# MM32SPINxxxx register map
Vendor: MindMotion Ltd.; Series: MM32SPIN; File version: 1.4
CPU: CM0 r0p0, little endian, no MPU, no FPU, 3 interrupt priority bits
Registers are 32-bit, read-write, reset 0x0 unless marked. A register's access mark holds for its fields unless they carry their own. Offsets are from the block's base; [hi:lo] are bit positions; {n}, {i} and the like mark numbered series.

## UART1 — Universal asynchronous receiver transmitter
Base 0x40013800
Same registers: UART2 0x40004400
0x00 TDR
  [7:0] TXREG — Transmit data register
0x04 RDR ro
  [7:0] RXREG — Receive data register
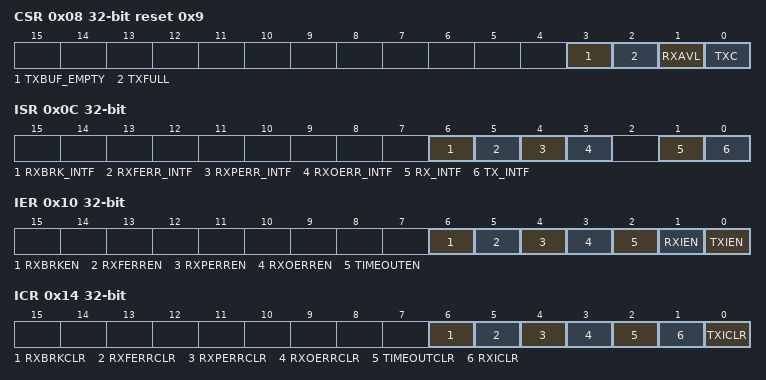
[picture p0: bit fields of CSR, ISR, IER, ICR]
0x08 CSR ro reset 0x9
  [3] TXBUF_EMPTY — Transmit buffer enpty flag bit
  [2] TXFULL — Transmit buffer full flag bit
  [1] RXAVL — Receive valid data flag bit
  [0] TXC — Transmit complete flag bit
0x0C ISR ro
  [6] RXBRK_INTF — Receive frame break interrupt flag bit
  [5] RXFERR_INTF — Frame error interrupt flag bit
  [4] RXPERR_INTF — Parity error interrupt flag bit
  [3] RXOERR_INTF — Receive overflow error interrupt flag bit
  [1] RX_INTF — Receive valid data interrupt flag bit
  [0] TX_INTF — Transmit buffer enpty interrupt flag bit
0x10 IER
  [6] RXBRKEN — Receive frame break interrupt enable bit
  [5] RXFERREN — Frame error interrupt enable bit
  [4] RXPERREN — Parity error interrupt enable bit
  [3] RXOERREN — Receive overflow error interrupt enable bit
  [2] TIMEOUTEN — Receive timeout interrupt enable bit
  [1] RXIEN — Receive buffer interrupt enable bit
  [0] TXIEN — Transmit buffer enpty interrupt enable bit
0x14 ICR wo
  [6] RXBRKCLR — Receive frame break interrupt clear bit
  [5] RXFERRCLR — Frame error interrupt clear bit
  [4] RXPERRCLR — Parity error interrupt clear bit
  [3] RXOERRCLR — Receive overflow error interrupt clear bit
  [2] TIMEOUTCLR — Receive timeout interrupt clear bit
  [1] RXICLR — Receive interrupt clear bit
  [0] TXICLR — Transmit buffer empty interrupt clear bit
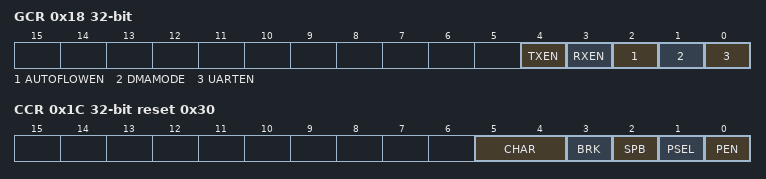
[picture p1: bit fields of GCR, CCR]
0x18 GCR
  [4] TXEN — Enable transmit
  [3] RXEN — Enable receive
  [2] AUTOFLOWEN — Automatic flow control enable bit
  [1] DMAMODE — DMA mode selection bit
  [0] UARTEN — UART mode selection bit
0x1C CCR reset 0x30
  [5:4] CHAR — UART width bit
  [3] BRK — UART transmit frame break
  [2] SPB — Stop bit selection
  [1] PSEL — Parity selection bit
  [0] PEN — Parity enable bit
0x20 BRR reset 0x1
  [15:0] DIV_Mantissa — UART baud rate control register
0x24 FRA
  [3:0] DIV_fraction — UART fractional-n control register

## ADC — Analog to digital converter
Base 0x40012400
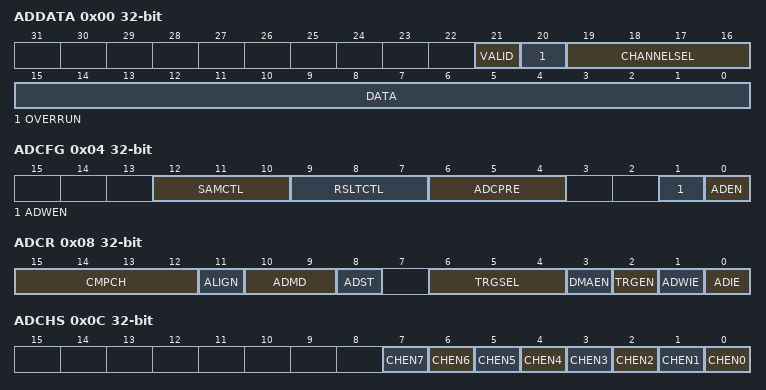
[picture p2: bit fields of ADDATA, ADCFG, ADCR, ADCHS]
0x00 ADDATA ro
  [21] VALID — Valid flag
  [20] OVERRUN — Overrun flag
  [19:16] CHANNELSEL — Channel selection
  [15:0] DATA — Transfer data
0x04 ADCFG
  [12:10] SAMCTL — Channel x Sample time selection
  [9:7] RSLTCTL — resolution
  [6:4] ADCPRE — ADC prescaler
  [1] ADWEN — ADC window comparison enable
  [0] ADEN — ADC enable
0x08 ADCR
  [15:12] CMPCH — Window comparison channel selection
  [11] ALIGN — Data alignment
  [10:9] ADMD — ADC mode
  [8] ADST — ADC start
  [6:4] TRGSEL — External trigger selection
  [3] DMAEN — Direct memory access enable
  [2] TRGEN — External trigger enable
  [1] ADWIE — ADC window comparator interrupt enable
  [0] ADIE — ADC interrupt enable
0x0C ADCHS
  [n] CHEN{n} (n=0..7) — Analog input channel {n} enable
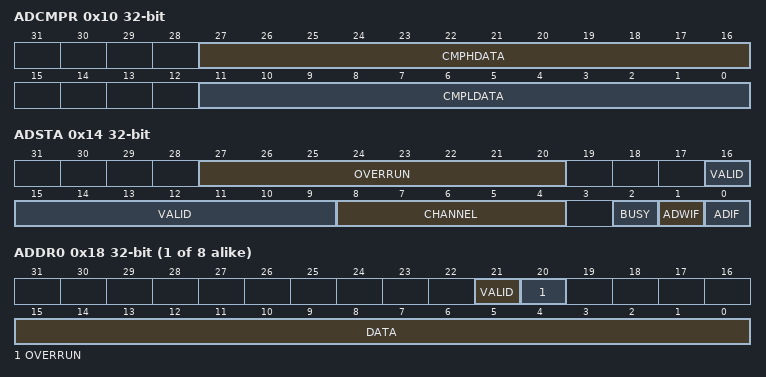
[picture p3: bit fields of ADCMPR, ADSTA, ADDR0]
0x10 ADCMPR
  [27:16] CMPHDATA — Compare data high limit
  [11:0] CMPLDATA — Compare data low limit
0x14 ADSTA ro
  [27:20] OVERRUN — Overrun flag
  [16:9] VALID — Valid flag
  [8:4] CHANNEL — Current conversion channel
  [2] BUSY
  [1] ADWIF — ADC window comparator interrupt flag
  [0] ADIF — ADC interrupt flag
{0x18+4i} ADDR{i} ro (i=0..7)
  [21] VALID — Valid flag
  [20] OVERRUN — Overrun flag
  [15:0] DATA — Transfer data

## USB — Universal serial bus full-speed device interface
Base 0x40005C00
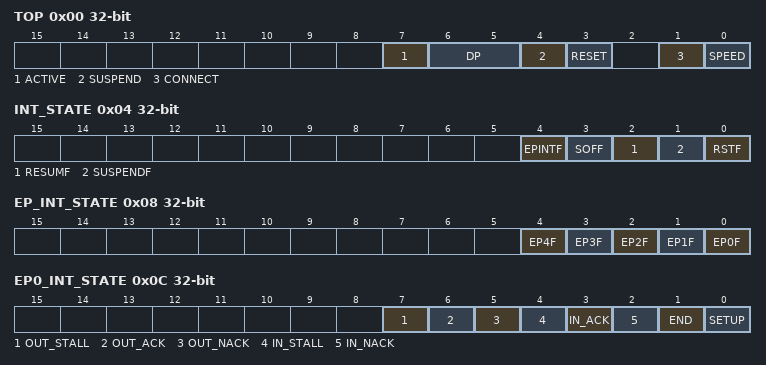
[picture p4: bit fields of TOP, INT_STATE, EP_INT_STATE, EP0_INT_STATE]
0x00 TOP
  [7] ACTIVE — USB bus is active
  [6:5] DP — Current USB DP/DM line state
  [4] SUSPEND — USB suspend state
  [3] RESET — Reset EP and FIFO in USB controller
  [1] CONNECT — USB connection
  [0] SPEED
0x04 INT_STATE ro
  [4] EPINTF — EP interrupt received
  [3] SOFF — BUS received
  [2] RESUMF — BUS resume received
  [1] SUSPENDF — BUS suspend received
  [0] RSTF — BUS reset received
0x08 EP_INT_STATE ro
  [n] EP{n}F (n=0..4) — EP{n} interrupt received
0x0C EP0_INT_STATE ro
  [7] OUT_STALL — OUT-STALL received
  [6] OUT_ACK — OUT-ACK received
  [5] OUT_NACK — OUT-NACK received
  [4] IN_STALL — IN-STALL received
  [3] IN_ACK — IN-ACK received
  [2] IN_NACK — IN-NACK received
  [1] END — Status stage finished
  [0] SETUP — SETUP packet received
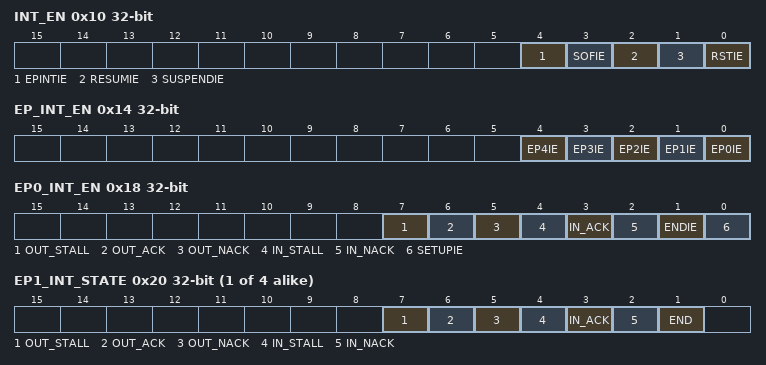
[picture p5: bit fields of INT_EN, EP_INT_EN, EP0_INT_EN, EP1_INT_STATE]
0x10 INT_EN
  [4] EPINTIE — EP interrupt enable
  [3] SOFIE — SOF interrupt enable
  [2] RESUMIE — BUS resume interrupt enable
  [1] SUSPENDIE — BUS suspend interrupt enable
  [0] RSTIE — BUS reset interrupt enable
0x14 EP_INT_EN
  [n] EP{n}IE (n=0..4) — EP{n} interrupt enable
0x18 EP0_INT_EN
  [7] OUT_STALL — OUT-STALL interrupt enable
  [6] OUT_ACK — OUT-ACK interrupt enable
  [5] OUT_NACK — OUT-NACK interrupt enable
  [4] IN_STALL — IN-STALL interrupt enable
  [3] IN_ACK — IN-ACK interrupt enable
  [2] IN_NACK — IN-NACK interrupt enable
  [1] ENDIE — Status stage finished interrupt enable
  [0] SETUPIE — SETUP packet interrupt enable
{0x1C+4i} EP{i}_INT_STATE (i=1..4)
  [7] OUT_STALL — OUT-STALL received
  [6] OUT_ACK — OUT-ACK received
  [5] OUT_NACK — OUT-NACK received
  [4] IN_STALL — IN-STALL received
  [3] IN_ACK — IN-ACK received
  [2] IN_NACK — IN-NACK received
  [1] END — Transfer finished
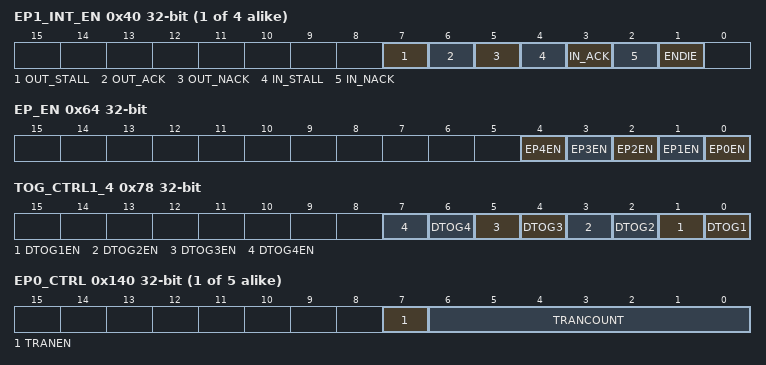
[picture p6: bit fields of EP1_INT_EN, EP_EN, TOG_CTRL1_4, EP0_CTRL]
{0x3C+4i} EP{i}_INT_EN (i=1..4)
  [7] OUT_STALL — OUT-STALL interrupt enable
  [6] OUT_ACK — OUT-ACK interrupt enable
  [5] OUT_NACK — OUT-NACK interrupt enable
  [4] IN_STALL — IN-STALL interrupt enable
  [3] IN_ACK — IN-ACK interrupt enable
  [2] IN_NACK — IN-NACK interrupt enable
  [1] ENDIE — Finished interrupt enable
0x60 ADDR
  [6:0] ADDR — USB address
0x64 EP_EN
  [n] EP{n}EN (n=0..4) — Enable End Point {n}
0x78 TOG_CTRL1_4
  [2n-1] DTOG{n}EN (n=1..4) — Set End Point {n} enable
  [2n-2] DTOG{n} (n=1..4) — Set End Point {n} Toggle
{0x80+4i} SETUP{i} ro (i=0..7)
  [7:0] SETUPD{i} — Setup Data {i}
0xA0 PACKET_SIZE reset 0x40
  [7:0] SIZE0 — USB DMA Max Packet Size
{0x100+4i} EP{i}_AVAIL ro (i=0..4)
  [7:0] EP{i}AVIL — EP{i} FIFO available data number
{0x140+4i} EP{i}_CTRL (i=0..4)
  [7] TRANEN — EP{i} transfer enable
  [6:0] TRANCOUNT — EP{i} transfer counter
{0x160+4i} EP{i}_FIFO (i=0..4)
  [7:0] EP{i}_FIFO — EP{i} FIFO port
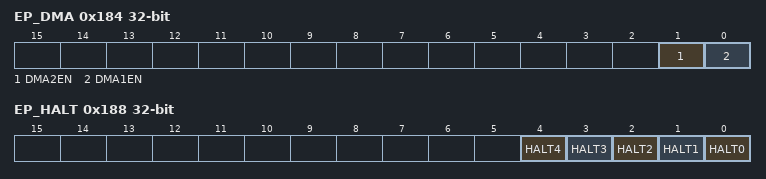
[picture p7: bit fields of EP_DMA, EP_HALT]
0x184 EP_DMA
  [1] DMA2EN — EP2 DMA enable
  [0] DMA1EN — EP1 DMA enable
0x188 EP_HALT
  [n] HALT{n} (n=0..4) — EP{n} halt

## DBG — Debug support
Base 0xE0042000
0x00 IDCODE ro
  [31:0] DEV_ID — Device identifier
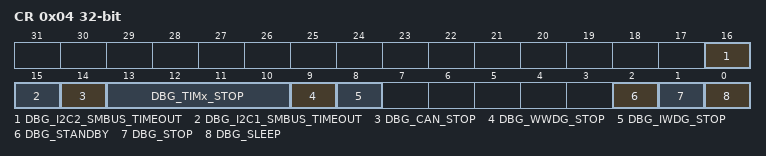
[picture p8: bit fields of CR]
0x04 CR wo
  [16] DBG_I2C2_SMBUS_TIMEOUT — SMBUS timeout mode stopped when Core is halted
  [15] DBG_I2C1_SMBUS_TIMEOUT — SMBUS timeout mode stopped when Core is halted
  [14] DBG_CAN_STOP — Debug CAN stopped when core is halted
  [13:10] DBG_TIMx_STOP — TIMx counter stopped when core is halted
  [9] DBG_WWDG_STOP — Debug window watchdog when core is halted
  [8] DBG_IWDG_STOP — Debug independent watchdog stopped when core is stopped
  [2] DBG_STANDBY — Debug Standby mode
  [1] DBG_STOP — Debug Stop mode
  [0] DBG_SLEEP — Debug Sleep mode

## CRS — Clock Recovery System
Base 0x40006C00
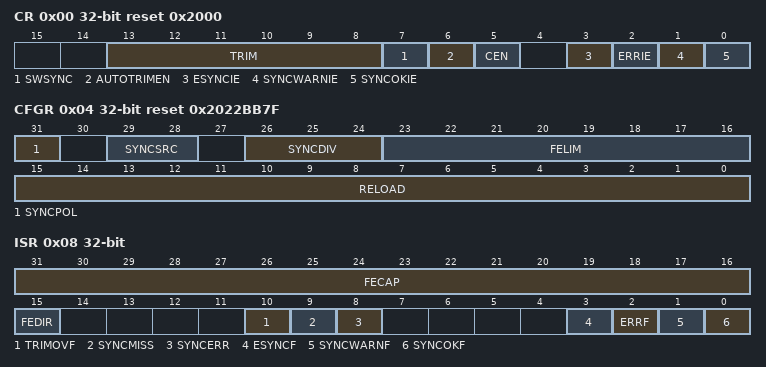
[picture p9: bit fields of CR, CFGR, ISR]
0x00 CR reset 0x2000
  [13:8] TRIM — HSI48 oscillator smooth trimming
  [7] SWSYNC — Generate software SYNC event
  [6] AUTOTRIMEN — Automatic trimming enable
  [5] CEN — Frequency error counter enable
  [3] ESYNCIE — Expected SYNC interrupt enable
  [2] ERRIE — Synchronization or trimming error interrupt enable
  [1] SYNCWARNIE — SYNC warning interrupt enable
  [0] SYNCOKIE — SYNC event OK interrupt enable
0x04 CFGR reset 0x2022BB7F
  [31] SYNCPOL — SYNC polarity selection
  [29:28] SYNCSRC — SYNC signal source selection
  [26:24] SYNCDIV — SYNC divider
  [23:16] FELIM — Frequency error limit
  [15:0] RELOAD — Counter reload value
0x08 ISR ro
  [31:16] FECAP — Frequency error capture
  [15] FEDIR — Frequency error direction
  [10] TRIMOVF — Trimming overflow or underflow
  [9] SYNCMISS — SYNC missed
  [8] SYNCERR — SYNC error
  [3] ESYNCF — Expected SYNC flag
  [2] ERRF — Error flag
  [1] SYNCWARNF — SYNC warning flag
  [0] SYNCOKF — SYNC event OK flag
0x0C ICR

## COMP — comparator
Base 0x40013C00
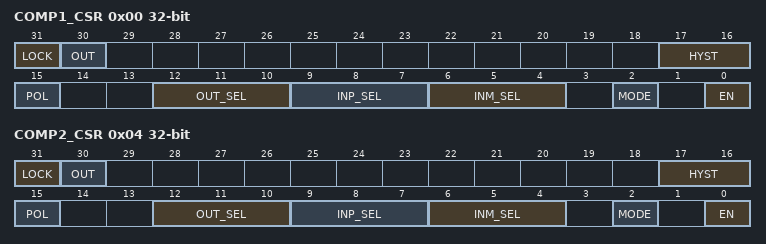
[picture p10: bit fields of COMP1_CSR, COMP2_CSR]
0x00 COMP1_CSR
  [31] LOCK — Comparator lock
  [30] OUT — Comparator 1 lock
  [17:16] HYST — Comparator 1 hysteresis
  [15] POL — Comparator 1 output polarity
  [12:10] OUT_SEL — Comparator 1 output selection
  [9:7] INP_SEL — Comparator 1 normal phase input selection
  [6:4] INM_SEL — Comparator 1 inverting input selection
  [2] MODE — Comparator 1 mode
  [0] EN — Comparator 1 enable
0x04 COMP2_CSR
  [31] LOCK — Comparator lock
  [30] OUT — Comparator 2 lock
  [17:16] HYST — Comparator 2 hysteresis
  [15] POL — Comparator 2 output polarity
  [12:10] OUT_SEL — Comparator 2 output selection
  [9:7] INP_SEL — Comparator 2 normal phase input selection
  [6:4] INM_SEL — Comparator 2 inverting input selection
  [2] MODE — Comparator 2 mode
  [0] EN — Comparator 2 enable
